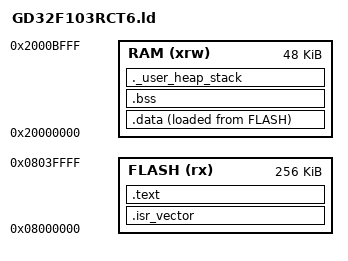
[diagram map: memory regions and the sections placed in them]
/* Linker script for GD32F103RCT6 / STM32F103RCT6 */
ENTRY(Reset_Handler)

MEMORY
{
  FLASH (rx) : ORIGIN = 0x08000000, LENGTH = 256K
  RAM (xrw)  : ORIGIN = 0x20000000, LENGTH = 48K
}

_estack = ORIGIN(RAM) + LENGTH(RAM);

SECTIONS
{
  .isr_vector : { KEEP(*(.isr_vector)) } > FLASH

  .text :
  {
    *(.text*)
    *(.rodata*)
    *(.glue_7)
    *(.glue_7t)
    *(.eh_frame)
    KEEP(*(.init))
    KEEP(*(.fini))
    . = ALIGN(4);
    _etext = .;
  } > FLASH

  _sidata = LOADADDR(.data);

  .data :
  {
    . = ALIGN(4);
    _sdata = .;
    *(.data*)
    . = ALIGN(4);
    _edata = .;
  } > RAM AT> FLASH

  .bss (NOLOAD) :
  {
    . = ALIGN(4);
    _sbss = .;
    *(.bss*)
    *(COMMON)
    . = ALIGN(4);
    _ebss = .;
  } > RAM

  ._user_heap_stack :
  {
    . = ALIGN(8);
    PROVIDE(end = .);
    PROVIDE(_end = .);
    . = . + 0x200; /* heap */
    . = . + 0x400; /* stack */
    . = ALIGN(8);
  } > RAM

  .ARM.attributes 0 : { *(.ARM.attributes) }
}
